# ISD9300_v3 register map
File version: 1.0
Registers are 32-bit, read-write, reset 0x0 unless marked. A register's access mark holds for its fields unless they carry their own. Offsets are from the block's base; [hi:lo] are bit positions.

## ANA — ANA Register Map
Base 0x40080000
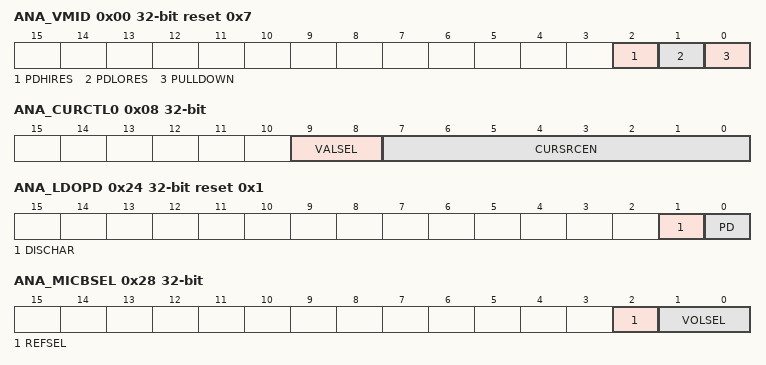
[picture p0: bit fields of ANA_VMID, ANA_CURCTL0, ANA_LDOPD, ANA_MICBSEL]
0x00 ANA_VMID reset 0x7 — VMID Reference Control Register
  [2] PDHIRES — Power Down High (360kΩ) Resistance Reference
    0=Connect the High Resistance reference to VMID. Use this setting for minimum power consumption; 1=The High Resistance reference is disconnected from VMID. Default power down and reset condition
  [1] PDLORES — Power Down Low (4.8kΩ) Resistance Reference
    0=Connect the Low Resistance reference to VMID. Use this setting for fast power up of VMID. Can be turned off after 50ms to save power; 1=The Low Resistance reference is disconnected from VMID. Default power down and reset condition
  [0] PULLDOWN — VMID Pulldown
    0=Release VMID pin for reference operation; 1=Pull VMID pin to ground. Default power down and reset condition
0x08 ANA_CURCTL0 — Current Source Control Register
  [9:8] VALSEL — Current Source Value. Select master current for source generation
    0=0.5 uA; 1=1 uA; 2=2.5 uA; 3=5 uA
  [7:0] CURSRCEN — Enable Current Source To GPIOB[X]. Individually enable current source to GPIOB pins. Each GPIOB pin has a separate current source.
    0=Disable; 1=Enable current source to pin GPIOB[x]
0x0C ANA_CURCTL1 — Current Source Control Register 1
  [15:0] CURSRCEN — Enable Current Source To GPIOB[X], GPIOA[X-4]. Individually enable current source to GPIO pins. Each GPIOB[11:0] and GPIOA[11:8] pin has a separate current source.
    0=Disable; 1=Enable current source to pin GPIOB[x] , x aaa 11~0; GPIOA[x-4] , x aaa 15~12
0x20 ANA_LDOSEL — LDO Voltage Select Register
  [1:0] LDOSEL — Select LDO Output Voltage. Note that maximum I/O pad operation speed only specified for voltage >2.4V.
    0=3.0V; 1=1.8V; 2=2.4V; 3=3.3V
0x24 ANA_LDOPD reset 0x1 — LDO Power Down Register
  [1] DISCHAR — Discharge
    0=No load on VD33; 1=Switch discharge resistor to VD33
  [0] PD — Power Down LDO. When powered down no current delivered to VD33.
    0=Enable LDO; 1=Power Down
0x28 ANA_MICBSEL — Microphone Bias Select Register
  [2] REFSEL — Select Reference Source For MICBIAS Generator. VMID provides superior noise performance for MICBIAS generation and should be used unless fixed voltage is absolutely necessary, then noise performance can be sacrificed and bandgap voltage used as reference.
    0=VMID aaa VCCA/2 is reference source; 1=VBG (bandgap voltage reference) is reference source
  [1:0] VOLSEL — Select Microphone Bias Voltage. MICBMODE aaa 0. 0: 90% VCCA. 1: 65% VCCA. 2: 75% VCCA. 3: 50% VCCA. MICBMODE aaa 1. 0: 2.4V. 1: 1.7V. 2: 2.0V. 3: 1.3V
0x2C ANA_MICBEN — Microphone Bias Enable Register
  [0] MICBEN — Enable Microphone Bias Generator
    0=Powered Down; 1=Enabled
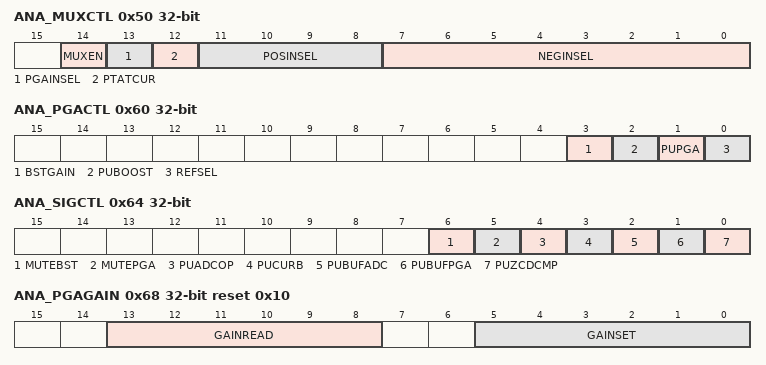
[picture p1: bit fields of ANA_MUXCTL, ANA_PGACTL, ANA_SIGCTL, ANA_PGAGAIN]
0x50 ANA_MUXCTL — Analog Multiplexer Control Register
  [14] MUXEN — Enable The Analog Multiplexer
    0=All channels disabled; 1=Selection determined by register setting
  [13] PGAINSEL — Select MICP/MICN To PGA Inputs
  [12] PTATCUR — Select PTAT Current. I_PTAT, to PGA_INN, negative input to PGA, for temperature measurement.
  [11:8] POSINSEL — Selects Connection Of GPIOB[7,5,3,1] To PGA_INP, Positive Input Of PGA. 1000b: GPIOB[7] connected to PGA_INP. 0100b: GPIOB[5] connected to PGA_INP. 0010b: GPIOB[3] connected to PGA_INP. 0001b: GPIOB[1] connected to PGA_INP
  [7:0] NEGINSEL — Selects Connection Of GPIOB[7:0] To PGA_INN, Negative Input Of PGA. If NEGINSEL[n] aaa 1 then GPIOB[n] is connected to PGA_INN.
0x60 ANA_PGACTL — PGA Enable Register
  [3] BSTGAIN — Boost Stage Gain Setting
    0=Gain aaa 0dB; 1=Gain aaa 26dB
  [2] PUBOOST — Power Up Control For Boost Stage Amplifier. This amplifier must be powered up for signal path operation.
    0=Power Down; 1=Power up
  [1] PUPGA — Power Up Control For PGA Amplifier. This amplifier must be powered up for signal path operation.
    0=Power Down; 1=Power up
  [0] REFSEL — Select Reference For Analog Path. Signal path is normally referenced to VMID (VCCA/2). To use an absolute reference this can be set to VBG aaa 1.2V.
    0=Select VMID voltage as analog ground reference; 1=Select Bandgap voltage as analog ground reference
0x64 ANA_SIGCTL — Signal Path Control Register
  [6] MUTEBST — Boost Stage Mute Control
    0=Normal; 1=Signal Muted
  [5] MUTEPGA — PGA Mute Control
    0=Normal; 1=Signal Muted
  [4] PUADCOP — Power Up ADC ΣΔ Modulator. This block must be powered up for ADC operation.
    0=Power down; 1=Power up
  [3] PUCURB — Power Up Control For Current Bias Generation. This block must be powered up for signal path operation.
    0=Power down; 1=Power up
  [2] PUBUFADC — Power Up Control For ADC Reference Buffer. This block must be powered up for signal path operation.
    0=Power down; 1=Power up
  [1] PUBUFPGA — Power Up Control For PGA Reference Buffer. This block must be powered up for signal path operation.
    0=Power down; 1=Power up
  [0] PUZCDCMP — Power Up And Enable Control For Zero Cross Detect Comparator. When enabled PGA gain settings will only be updated when ADC input signal crosses zero signal threshold. To operate ZCD the ALC peripheral clock (CLK_APBCLK0.BQALCKEN) must also be enabled and BIQ_CTL.DLCOEFF aaa 1 to allow ZCD clocks to be generated.
    0=Power down; 1=Power up and enable zero cross detection
0x68 ANA_PGAGAIN reset 0x10 — PGA Gain Select Register
  [13:8] GAINREAD — Current PGA Gain Value. Read Only. May be different from GAIN register when AGC is enabled and is controlling the PGA gain.
  [5:0] GAINSET — Select The PGA Gain Setting. From -12dB to 35.25dB in 0.75dB step size. 0x00 is lowest gain setting at -12dB and 0x3F is largest gain at 35.25dB.
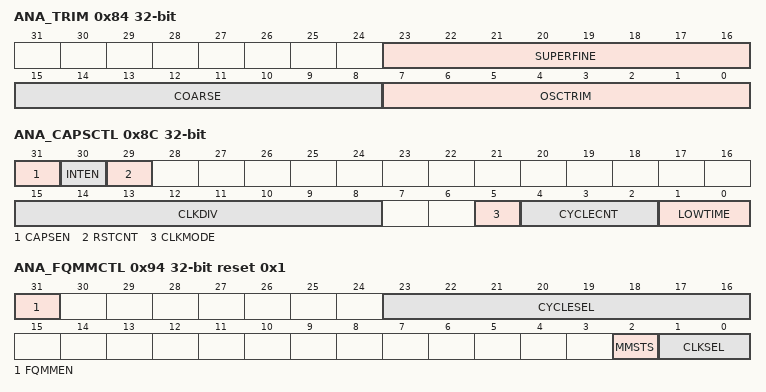
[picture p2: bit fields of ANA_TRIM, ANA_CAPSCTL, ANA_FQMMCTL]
0x84 ANA_TRIM (reset mask 0xFFFF0000) — Oscillator Trim Register
  [23:16] SUPERFINE — Superfine. The SUPERFINE trim setting is an 8bit signed integer. It adjusts the master oscillator by dithering the FINE trim setting between the current setting and one setting above (values 1,127) or below (values -1, -128) the current trim setting. Each step effectively moves the frequency 1/128th of the full FINE trim step size.
  [15:8] COARSE — COARSE. Current COARSE range setting of the oscillator. Read Only
  [7:0] OSCTRIM — Oscillator Trim. Reads current oscillator trim setting. Read Only.
0x8C ANA_CAPSCTL — Capacitive Touch Sensing Control Register
  [31] CAPSEN — Enable
    0=Disable/Reset block; 1=Enable Block
  [30] INTEN — Interrupt Enable
    0=Disable/Reset CAPS_IRQ interrupt; 1=Enable CAPS_IRQ interrupt
  [29] RSTCNT — Reset Count. 0: Release/Activate CAP_CNT. 1: Set high to reset CAP_CNT.
  [15:8] CLKDIV — Reference Clock Divider. Circuit can be used to generate a reference clock output of SDCLK/2/(CLKDIV+1) instead of a Capacitive Touch Sensing reset signal.
  [5] CLKMODE — Reference Clock Mode
    0=Capacitive Touch Sensing Mode; 1=Circuit is in Reference clock generation mode
  [4:2] CYCLECNT — Number Of Relaxation Cycles. Peripheral performs 2^(CYCLECNT) relaxation cycles before generating interrupt.
  [1:0] LOWTIME — Output Low Time. Number of PCLK cycles to discharge external capacitor.
    0=1cycle; 1=2cycles; 2=8cycles; 3=16cycles
0x90 ANA_CAPSCNT ro — Capacitive Touch Sensing Count Register
  [23:0] CAPSCNT — Counter Read Back Value Of Capacitive Touch Sensing Block
0x94 ANA_FQMMCTL reset 0x1 — Frequency Measurement Control Register
  [31] FQMMEN
    0=Disable/Reset block; 1=Start Frequency Measurement
  [23:16] CYCLESEL — Frequency Measurement Cycles. Number of reference clock periods plus one to measure target clock (PCLK). For example if reference clock is OSC32K (T is 30.5175us), set CYCLESEL to 7, then measurement period would be 30.5175*(7+1), 244.1us.
  [2] MMSTS — Measurement Done
    0=Measurement Ongoing; 1=Measurement Complete
  [1:0] CLKSEL — Reference Clock Source. 00b: OSC16K, 01b: OSC32K (default), 1xb: I2S_WS - can be GPIOA[4,8,12] according to SYS_GPA_MFP register, configure I2S in SLAVE mode to enable.
0x98 ANA_FQMMCNT ro — Frequency Measurement Count Register
  [15:0] FQMMCNT — Frequency Measurement Count. When MMSTS aaa 1 and FQMMEN aaa 1, this is number of PCLK periods counted for frequency measurement. The frequency will be PCLK aaa FQMMCNT * Fref /(CYCLESEL+1) Hz. Maximum resolution of measurement is Fref /(CYCLESEL+1)*2 Hz
0x9C ANA_FQMMCYC — Frequency Measurement Cycle Register
  [23:0] FQMMCYC — Frequency Measurement Cycles. Number of reference clock periods plus one to measure target clock (PCLK). For example if reference clock is OSC32K (T aaa 30.5175µs), FQMMCYC aaa 7, then measurement period would be 30.5175*(7+1) aaa 244.1µs. This address access same register as ANA_FQMMCTL but allows access to more bits of register.
